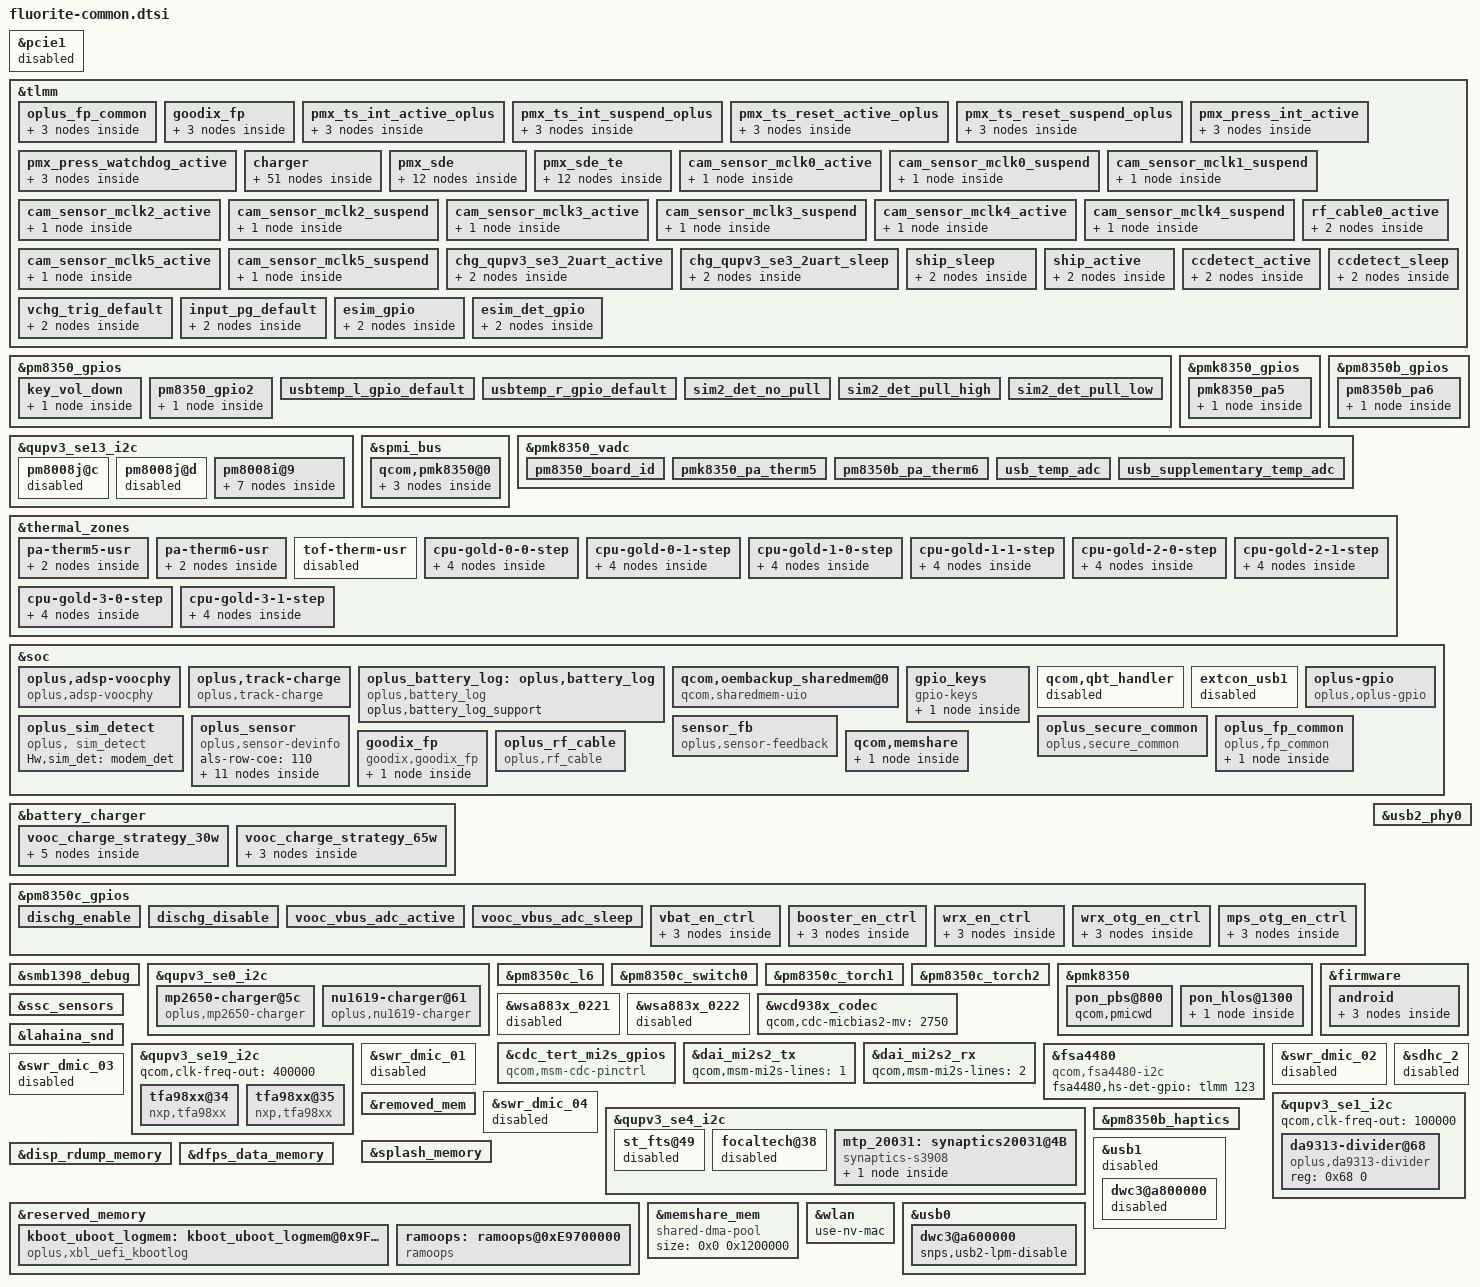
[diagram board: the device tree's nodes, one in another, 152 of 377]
//lahaina-pcie.dtsi
&pcie1 {
		status = "disabled";
};



//lahaina-pinctrl.dtsi

&tlmm {
	//#ifdef OPLUS_FEATURE_FINGERPRINT
	oplus_fp_common{
		gpio_id2_default: gpio_id2_default {
			mux {
				pins = "gpio119";
				function = "gpio";
			};
			config {
				pins = "gpio119";
				drive-strength = <2>;
				bias-pull-up;
				input-enable;
			};
		};
	};
	goodix_fp{
		gpio_goodix_irq_default: gpio_goodix_irq_default {
			mux {
				pins = "gpio38";
				function = "gpio";
			};
			config {
				pins = "gpio38";
				drive-strength = <2>;
				bias-disable;
				input-enable;
			};
		};
	};
	//#endif /*OPLUS_FEATURE_FINGERPRINT*/

	/* add pingrp for touchscreen */
	pmx_ts_int_active_oplus {
		ts_int_active: ts_int_active {
			mux {
				pins = "gpio23";
				function = "gpio";
			};

			config {
				pins = "gpio23";
				drive-strength = <8>;
				bias-disable;
				input-enable;
			};
		};
	};

	pmx_ts_int_suspend_oplus {
		ts_int_suspend1: ts_int_suspend1 {
			mux {
				pins = "gpio23";
				function = "gpio";
			};

			config {
				pins = "gpio23";
				drive-strength = <8>;
				//bias-pull-down;
				bias-pull-up;
				input-enable;
			};
		};
	};

	pmx_ts_reset_active_oplus {
		ts_reset_active: ts_reset_active {
			mux {
				pins = "gpio22";
				function = "gpio";
			};

			config {
				pins = "gpio22";
				drive-strength = <8>;
				output-low;
				bias-disable;
			};
		};
	};

	pmx_ts_reset_suspend_oplus {
		ts_reset_suspend1: ts_reset_suspend1 {
			mux {
				pins = "gpio22";
				function = "gpio";
			};

			config {
				pins = "gpio22";
				drive-strength = <2>;
				bias-pull-down;
			};
		};
	};


	pmx_press_int_active {
		press_int_active: press_int_active {
			mux {
				pins = "gpio51";
				function = "gpio";
			};

			config {
				pins = "gpio51";
				drive-strength = <2>;
				bias-disable;
				input-enable;
			};
		};
	};

	pmx_press_watchdog_active {
		watchdog_active: watchdog_active {
			mux {
				pins = "gpio97";
				function = "gpio";
			};

			config {
				pins = "gpio97";
				drive-strength = <2>;
				bias-disable;
				output-high;
			};
		};
	};


// #ifdef OPLUS_FEATURE_CHG_BASIC
	charger {
		idt_int_active: idt_int_active {
			mux {
				pins = "gpio7";
				function = "gpio";
			};

			config {
				pins = "gpio7";
				drive-strength = <2>;
				input-enable;
				/*bias-pull-up; PULL UP*/
				bias-disable;
			};
		};

		idt_int_sleep: idt_int_sleep {
			mux {
				pins = "gpio7";
				function = "gpio";
			};

			config {
				pins = "gpio7";
				drive-strength = <2>;
				bias-disable;
			};
		};

		idt_int_default: idt_int_default {
			mux {
				pins = "gpio7";
				function = "gpio";
			};

			config {
				pins = "gpio7";
				drive-strength = <2>;
				bias-disable;
			};
		};

		idt_connect_active: idt_connect_active {
			mux {
				pins = "gpio116";
				function = "gpio";
			};

			config {
				pins = "gpio116";
				drive-strength = <2>;
				bias-disable;
				input-enable;
				/*bias-pull-up; PULL UP*/
			};
		};

		idt_connect_sleep: idt_connect_sleep {
			mux {
				pins = "gpio116";
				function = "gpio";
			};

			config {
				pins = "gpio116";
				drive-strength = <2>;
				bias-disable;
			};
		};

		idt_connect_default: idt_connect_default {
			mux {
				pins = "gpio116";
				function = "gpio";
			};

			config {
				pins = "gpio116";
				drive-strength = <2>;
				bias-disable;
			};
		};
		vt_sleep_active: vt_sleep_active {
			mux {
				pins = "gpio46";
				function = "gpio";
			};

			config {
				pins = "gpio46";
				drive-strength = <2>;
				bias-pull-up;
			};
		};

		vt_sleep_sleep: vt_sleep_sleep {
			mux {
				pins = "gpio46";
				function = "gpio";
			};

			config {
				pins = "gpio46";
				drive-strength = <2>;
				bias-pull-down;
			};
		};

		vt_sleep_default: vt_sleep_default {
			mux {
				pins = "gpio46";
				function = "gpio";
			};

			config {
				pins = "gpio46";
				drive-strength = <2>;
				bias-pull-up;
			};
		};

		ext2_wireless_otg_en_active: ext2_wireless_otg_en_active {
			mux {
				pins = "gpio85";
				function = "gpio";
			};

			config {
				pins = "gpio85";
				drive-strength = <2>;
				bias-disable;
			};
		};

		ext2_wireless_otg_en_sleep: ext2_wireless_otg_en_sleep {
			mux {
				pins = "gpio85";
				function = "gpio";
			};

			config {
				pins = "gpio85";
				drive-strength = <2>;
				bias-disable;
			};
		};

		ext2_wireless_otg_en_default: ext2_wireless_otg_en_default {
			mux {
				pins = "gpio85";
				function = "gpio";
			};

			config {
				pins = "gpio85";
				drive-strength = <2>;
				bias-disable;
			};
		};

		ext1_wired_otg_en_active: ext1_wired_otg_en_active {
			mux {
				pins = "gpio26";
				function = "gpio";
			};

			config {
				pins = "gpio26";
				drive-strength = <2>;
				bias-disable;
			};
		};

		ext1_wired_otg_en_sleep: ext1_wired_otg_en_sleep {
			mux {
				pins = "gpio26";
				function = "gpio";
			};

			config {
				pins = "gpio26";
				drive-strength = <2>;
				bias-disable;
			};
		};

		ext1_wired_otg_en_default: ext1_wired_otg_en_default {
			mux {
				pins = "gpio26";
				function = "gpio";
			};

			config {
				pins = "gpio26";
				drive-strength = <2>;
				bias-disable;
			};
		};

		wls_pg_default: wls_pg_default {
			mux {
				pins = "gpio164";
				function = "gpio";
			};

			config {
				pins = "gpio164";
				drive-strength = <2>;
				bias-disable;
				output-high;
			};
		};

		wls_pg_active: wls_pg_active {
			mux {
				pins = "gpio164";
				function = "gpio";
			};

			config {
				pins = "gpio164";
				drive-strength = <2>;
				bias-disable;
				output-low;
			};
		};
	};
// #endif OPLUS_FEATURE_CHG_BASIC

	pmx_sde: pmx_sde {
		sde_dsi_active: sde_dsi_active {
			mux {
				pins = "gpio24";
				function = "gpio";
			};

			config {
				pins = "gpio24";
				drive-strength = <8>;   /* 8 mA */
				bias-disable = <0>;   /* no pull */
			};
		};

		sde_dsi_suspend: sde_dsi_suspend {
			mux {
				pins = "gpio24";
				function = "gpio";
			};

			config {
				pins = "gpio24";
				drive-strength = <2>;   /* 2 mA */
				bias-pull-down;         /* PULL DOWN */
			};
		};

		sde_dsi1_active: sde_dsi1_active {
			mux {
				pins = "gpio25";
				function = "gpio";
			};

			config {
				pins = "gpio25";
				drive-strength = <8>;   /* 8 mA */
				bias-disable = <0>;   /* no pull */
			};
		};

		sde_dsi1_suspend: sde_dsi1_suspend {
			mux {
				pins = "gpio25";
				function = "gpio";
			};

			config {
				pins = "gpio25";
				drive-strength = <2>;   /* 2 mA */
				bias-pull-down;         /* PULL DOWN */
			};
		};
	};

	pmx_sde_te: pmx_sde_te {
		sde_te_active: sde_te_active {
			mux {
				pins = "gpio82";
				function = "mdp_vsync";
			};

			config {
				pins = "gpio82";
				drive-strength = <2>;   /* 2 mA */
				bias-pull-down;         /* PULL DOWN */
			};
		};

		sde_te_suspend: sde_te_suspend {
			mux {
				pins = "gpio82";
				function = "mdp_vsync";
			};

			config {
				pins = "gpio82";
				drive-strength = <2>;   /* 2 mA */
				bias-pull-down;         /* PULL DOWN */
			};
		};

		sde_te1_active: sde_te1_active {
			mux {
				pins = "gpio83";
				function = "mdp_vsync";
			};

			config {
				pins = "gpio83";
				drive-strength = <2>;   /* 2 mA */
				bias-pull-down;         /* PULL DOWN */
			};
		};

		sde_te1_suspend: sde_te1_suspend {
			mux {
				pins = "gpio83";
				function = "mdp_vsync";
			};

			config {
				pins = "gpio83";
				drive-strength = <2>;   /* 2 mA */
				bias-pull-down;         /* PULL DOWN */
			};
		};
	};

	cam_sensor_mclk0_active {

		config {
			/* #ifdef OPLUS_FEATURE_CAMERA_COMMON */
			drive-strength = <6>; /* 6 MA */
			/* #else */
			// drive-strength = <2>; /* 2 MA */
			/* #endif */
		};
	};
	cam_sensor_mclk0_suspend {

		config {
			/* #ifdef OPLUS_FEATURE_CAMERA_COMMON */
			drive-strength = <6>; /* 6 MA */
			/* #else */
			// drive-strength = <2>; /* 2 MA */
			/* #endif */
		};
	};
	cam_sensor_mclk1_suspend {

		config {
			/* #ifdef OPLUS_FEATURE_CAMERA_COMMON */
			drive-strength = <6>; /* 6 MA */
			/* #else */
			// drive-strength = <2>; /* 2 MA */
			/* #endif */
		};
	};

	cam_sensor_mclk2_active {

		config {
			/* #ifdef OPLUS_FEATURE_CAMERA_COMMON */
			drive-strength = <6>; /* 6 MA */
			/* #else */
			// drive-strength = <2>; /* 2 MA */
			/* #endif */
		};
	};

	cam_sensor_mclk2_suspend {

		config {
			/* #ifdef OPLUS_FEATURE_CAMERA_COMMON */
			drive-strength = <6>; /* 6 MA */
			/* #else */
			// drive-strength = <2>; /* 2 MA */
			/* #endif */
		};
	};

	cam_sensor_mclk3_active {

		config {
			/* #ifdef OPLUS_FEATURE_CAMERA_COMMON */
			drive-strength = <6>; /* 6 MA */
			/* #else */
			// drive-strength = <2>; /* 2 MA */
			/* #endif */
		};
	};

	cam_sensor_mclk3_suspend {

		config {
			/* #ifdef OPLUS_FEATURE_CAMERA_COMMON */
			drive-strength = <6>; /* 6 MA */
			/* #else */
			// drive-strength = <2>; /* 2 MA */
			/* #endif */
		};
	};

	cam_sensor_mclk4_active {

		config {
			/* #ifdef OPLUS_FEATURE_CAMERA_COMMON */
			drive-strength = <6>; /* 6 MA */
			/* #else */
			// drive-strength = <2>; /* 2 MA */
			/* #endif */
		};
	};

	cam_sensor_mclk4_suspend {

		config {
			/* #ifdef OPLUS_FEATURE_CAMERA_COMMON */
			drive-strength = <6>; /* 6 MA */
			/* #else */
			// drive-strength = <2>; /* 2 MA */
			/* #endif */
		};
	};

	cam_sensor_mclk5_active {

		config {
			/* #ifdef OPLUS_FEATURE_CAMERA_COMMON */
			drive-strength = <6>; /* 6 MA */
			/* #else */
			// drive-strength = <2>; /* 2 MA */
			/* #endif */
		};
	};

	cam_sensor_mclk5_suspend {

		config {
			/* #ifdef OPLUS_FEATURE_CAMERA_COMMON */
			drive-strength = <6>; /* 6 MA */
			/* #else */
			// drive-strength = <2>; /* 2 MA */
			/* #endif */
		};
	};

	rf_cable0_active: rf_cable0_active {
		mux {
			pins = "gpio91";
			function = "gpio";
		};
		config {
			pins = "gpio91";
			drive-strength = <2>;
			input-enable;
			bias-pull-up;
		};
	};
};



//lahaina-pmic-overlay.dtsi
&pm8350_gpios {
	///delete-node/ key_vol_up;
	key_vol_down {
		key_vol_down_default: key_vol_down_default {
			pins = "gpio6";
			function = "normal";
			input-enable;
			bias-pull-up;
			power-source = <1>;
		};
	};
};

&qupv3_se13_i2c {
	pm8008j@c {
		status = "disabled";
	};

	pm8008j@d {
		status = "disabled";
	};

	pm8008i@9 {

		qcom,pm8008i-regulator {
			vdd_l3_l4-supply = <&S1C>;
			vdd_l5-supply = <&BOB>;


			//L2I: pm8008i_l2: regulator@4100 {
			regulator@4100 {
				reg = <0x4100>;
				regulator-name = "pm8008i_l2";
				regulator-min-microvolt = <944000>;
				regulator-max-microvolt = <1256000>;
				qcom,min-dropout-voltage = <150000>;
				qcom,hpm-min-load = <30000>;
			};

			//L3I: pm8008i_l3: regulator@4200 {
			regulator@4200 {
				reg = <0x4200>;
				regulator-name = "pm8008i_l3";
				regulator-min-microvolt = <1696000>;
				regulator-max-microvolt = <1800000>;
				qcom,min-dropout-voltage = <70000>;
			};

			//L4I: pm8008i_l4: regulator@4300 {
			regulator@4300 {
				reg = <0x4300>;
				regulator-name = "pm8008i_l4";
				regulator-min-microvolt = <1696000>;
				regulator-max-microvolt = <1800000>;
				qcom,min-dropout-voltage = <70000>;
			};

			//L5I: pm8008i_l5: regulator@4400 {
			regulator@4400 {
				reg = <0x4400>;
				regulator-name = "pm8008i_l5";
				regulator-min-microvolt = <2696000>;
				regulator-max-microvolt = <3000000>;
				qcom,min-dropout-voltage = <200000>;
			};

			//L6I: pm8008i_l6: regulator@4500 {
			regulator@4500 {
				reg = <0x4500>;
				regulator-name = "pm8008i_l6";
				regulator-min-microvolt = <2696000>;
				regulator-max-microvolt = <3000000>;
/*endif*/
				qcom,min-dropout-voltage = <200000>;
			};

			//L7I: pm8008i_l7: regulator@4600 {
			regulator@4600 {
				reg = <0x4600>;
				regulator-name = "pm8008i_l7";
				regulator-min-microvolt = <2696000>;
				regulator-max-microvolt = <3000000>;
				qcom,min-dropout-voltage = <200000>;
			};
		};
	};

};



&pm8350_gpios {

	pm8350_gpio2 {
		pm8350_gpio2_default: pm8350_gpio2_default {
			pins = "gpio2";
			bias-high-impedance;
		};
	};
};

&pmk8350_gpios {
	pmk8350_pa5 {
		pmk8350_pa5_therm_default: pmk8350_pa5_therm_default {
			pins = "gpio3";
			bias-high-impedance;
		};
	};

};

&pm8350b_gpios {
	pm8350b_pa6 {
		pm8350b_pa6_therm_default: pm8350b_pa6_therm_default {
			pins = "gpio1";
			bias-high-impedance;
		};
	};

};

&spmi_bus {
	qcom,pmk8350@0 {
		pm8350_adc_tm_iio: adc_tm_iio@3400 {
			/* Alternate ADC_TM DT node */
			compatible = "qcom,adc-tm7-iio";
			/* With this entry, a feature-reduced
			version of the driver is initialized (only
			thermistor reads, no interrupt functionality
			for exposed thermistors) */
			reg = <0x3400>;
			#thermal-sensor-cells = <1>;
			#address-cells = <1>;
			#size-cells = <0>;
			io-channels = <&pmk8350_vadc PM8350B_ADC7_GPIO1_100K_PU>,
				      <&pmk8350_vadc PMK8350_ADC7_AMUX_THM4_100K_PU>;
			/* Similar to io-channels in actual ADC_TM node,
			for reading thermistor temperature from
			VADC */

			pm8350b_pa_therm6 {
				/* ADC_TM child node, similar to previous */
				reg = <PM8350B_ADC7_GPIO1_100K_PU>;
				qcom,ratiometric;
				qcom,hw-settle-time = <200>;
			};
			pmk8350_pa_therm5 {
				/* ADC_TM child node, similar to previous */
				reg = <PMK8350_ADC7_AMUX_THM4_100K_PU>;
				qcom,ratiometric;
				qcom,hw-settle-time = <200>;
			};

		};
	};
};

&pmk8350_vadc {
	pinctrl-names = "default";
	//pinctrl-0 = <&pm8350_rear_tof_therm_default>;
	pinctrl-0 = <&pm8350_gpio2_default &pmk8350_pa5_therm_default &pm8350b_pa6_therm_default>;

	pm8350_board_id {
		reg = <PM8350_ADC7_GPIO1>;
		label = "pm8350_board_id";
		//qcom,ratiometric;
		qcom,hw-settle-time = <200>;
		qcom,pre-scaling = <1 1>;
	};

	pmk8350_pa_therm5 {
		reg = <PMK8350_ADC7_AMUX_THM4_100K_PU>;
		label = "pmk8350_pa_therm5";
		qcom,ratiometric;
		qcom,hw-settle-time = <200>;
		qcom,pre-scaling = <1 1>;
	};

	pm8350b_pa_therm6 {
		reg = <PM8350B_ADC7_GPIO1_100K_PU>;
		label = "pm8350b_pa_therm6";
		qcom,ratiometric;
		qcom,hw-settle-time = <200>;
		qcom,pre-scaling = <1 1>;
	};
};

&thermal_zones {
	pa-therm5-usr {
		polling-delay-passive = <0>;
		polling-delay = <0>;
		thermal-governor = "user_space";
		thermal-sensors = <&pm8350_adc_tm_iio PMK8350_ADC7_AMUX_THM4_100K_PU>;
		/* phandle and channel number of added channel */
		wake-capable-sensor;
		trips {
			active-config0 {
				temperature = <55000>;
				hysteresis = <1000>;
				type = "passive";
			};
		};
	};

	pa-therm6-usr {
		polling-delay-passive = <0>;
		polling-delay = <0>;
		thermal-governor = "user_space";
		thermal-sensors = <&pm8350_adc_tm_iio PM8350B_ADC7_GPIO1_100K_PU>;
		/* phandle and channel number of added channel */
		wake-capable-sensor;
		trips {
			active-config0 {
				temperature = <55000>;
				hysteresis = <1000>;
				type = "passive";
			};
		};
	};
};

&soc {
	oplus,adsp-voocphy {
		compatible = "oplus,adsp-voocphy";
	};
};

&battery_charger {
	//for oplus chg framework:
        oplus,chg_ops = "ext-mp2650";
	qcom,smart_charging_screenoff;
	qcom,voocphy_support = <1>;
	qcom,input_current_charger_ma = <2000>;
	qcom,pd_input_current_charger_ma = <2000>;
	qcom,qc_input_current_charger_ma = <2000>;

	qcom,input_current_usb_ma = <500>;

	qcom,input_current_cdp_ma = <1500>;
	qcom,input_current_led_ma = <1200>;
	qcom,input_current_led_ma_high = <1800>;
	qcom,input_current_led_ma_warm = <1800>;
	qcom,input_current_led_ma_normal = <2000>;
	qcom,led_warm_bat_decidegc = <350>;
	qcom,led_high_bat_decidegc = <370>;

	qcom,input_current_camera_ma = <1200>;

	qcom,input_current_vooc_led_ma_high = <1800>;
	qcom,input_current_vooc_led_ma_warm = <1800>;
	qcom,input_current_vooc_led_ma_normal = <3600>;
	qcom,input_current_vooc_ma_normal = <3600>;
	qcom,vooc_temp_bat_normal_decidegc = <350>;
	qcom,input_current_vooc_ma_warm = <3200>;
	qcom,vooc_temp_bat_warm_decidegc = <370>;
	qcom,input_current_vooc_ma_high = <2200>;
	qcom,vooc_temp_bat_hot_decidegc = <440>;

	qcom,charger_current_vooc_ma_normal = <1800>;

	qcom,chg_ctrl_by_calling;
	qcom,input_current_calling_ma = <1500>;

	//qcom,input_current_led_ma_overtemp = <900>;
	qcom,overtemp_bat_decidegc = <350>;
	qcom,iterm_disabled = <0>;
	qcom,iterm_ma = <130>;
	qcom,recharge-mv = <100>;
	qcom,batt_capacity_mah = <4500>;/*typical capacity*/
	//qcom,batt_capacity_mah = <4400>; /*rated capacity*/

	qcom,removed_bat_decidegc = <190>;  /*<-19C*/

	qcom,cold_bat_decidegc = <20>;  /*-2C~0C*/
	qcom,temp_cold_vfloat_mv = <3980>;
	qcom,temp_cold_fastchg_current_ma = <300>;

	qcom,little_cold_bat_decidegc = <0>;	/*0C~5C*/
	qcom,temp_little_cold_vfloat_mv = <4435>;
	qcom,temp_little_cold_fastchg_current_ma_high = <1100>;
	qcom,temp_little_cold_fastchg_current_ma_low = <1100>;
	qcom,temp_little_cold_fastchg_current_ma = <1100>;
	qcom,pd_temp_little_cold_fastchg_current_ma_high = <2000>;
	qcom,pd_temp_little_cold_fastchg_current_ma_low = <1450>;
	qcom,qc_temp_little_cold_fastchg_current_ma_high = <2000>;
	qcom,qc_temp_little_cold_fastchg_current_ma_low = <1450>;

	qcom,cool_bat_decidegc = <50>;	/*5C~12C*/
	qcom,temp_cool_vfloat_mv = <4435>;
	qcom,temp_cool_fastchg_current_ma_high = <1100>;
	qcom,temp_cool_fastchg_current_ma_low = <1100>;
	qcom,pd_temp_cool_fastchg_current_ma_high = <2000>;
	qcom,pd_temp_cool_fastchg_current_ma_low = <2000>;
	qcom,qc_temp_cool_fastchg_current_ma_high = <2000>;
	qcom,qc_temp_cool_fastchg_current_ma_low = <2000>;

	qcom,little_cool_bat_decidegc = <120>;	/*12C~16C*/
	qcom,temp_little_cool_vfloat_mv = <4435>;
	qcom,temp_little_cool_fastchg_current_ma = <1100>;
	qcom,pd_temp_little_cool_fastchg_current_ma = <2000>;
	qcom,qc_temp_little_cool_fastchg_current_ma = <2000>;

	qcom,normal_bat_decidegc = <160>;	/*16C~44C*/
	qcom,temp_normal_fastchg_current_ma = <1100>;
	qcom,temp_normal_vfloat_mv = <4435>;
	qcom,pd_temp_normal_fastchg_current_ma = <2000>;
	qcom,qc_temp_normal_fastchg_current_ma = <2000>;

	qcom,warm_bat_decidegc = <450>;		/*45C~53C*/ /*8pin Bat Vooc project need add 3 degree C*/
	qcom,temp_warm_vfloat_mv = <4130>;
	qcom,temp_warm_fastchg_current_ma = <600>;
	qcom,pd_temp_warm_fastchg_current_ma = <600>;
	qcom,qc_temp_warm_fastchg_current_ma = <600>;
	qcom,temp_warm_fastchg_current_ma_led_on = <250>;

	qcom,hot_bat_decidegc = <530>;

	qcom,non_standard_vfloat_mv = <3980>;
	qcom,non_standard_fastchg_current_ma = <512>;

	qcom,short_c_bat_cv_mv = <4330>;
	qcom,short_c_bat_vfloat_mv = <3800>;
	qcom,short_c_bat_fastchg_current_ma = <512>;

	qcom,cold_vfloat_sw_limit = <3930>;
	qcom,little_cold_vfloat_sw_limit = <4385>;
	qcom,cool_vfloat_sw_limit = <4385>;
	qcom,little_cool_vfloat_sw_limit = <4385>;
	qcom,normal_vfloat_sw_limit = <4385>;
	qcom,warm_vfloat_sw_limit = <4080>;
	qcom,non_standard_vfloat_sw_limit = <3930>;
	qcom,short_c_bat_vfloat_sw_limit = <3750>;

	qcom,max_chg_time_sec = <36000>;
	qcom,charger_hv_thr = <9900>;
	qcom,charger_recv_thr = <9500>;
	qcom,charger_lv_thr = <3400>;
	qcom,vbatt_full_thr = <4435>;
	qcom,vbatt_hv_thr = <4600>;
	qcom,vfloat_step_mv = <8>;
	qcom,non_standard_vfloat_over_sw_limit = <3990>;
	qcom,cold_vfloat_over_sw_limit = <3990>;
	qcom,little_cold_vfloat_over_sw_limit = <4445>;
	qcom,cool_vfloat_over_sw_limit = <4445>;
	qcom,little_cool_vfloat_over_sw_limit = <4445>;
	qcom,normal_vfloat_over_sw_limit = <4445>;
	qcom,warm_vfloat_over_sw_limit = <4140>;

	qcom,vbatt_power_off = <3300>;
	qcom,vbatt_soc_1 = <3310>;
	qcom,vooc_project = <3>;
	qcom,vbatt_num = <2>;
	qcom,ffc_support;
	qcom,dual_ffc;
	recharge_after_full;
	qcom,wireless_support;
	qcom,wpc_no_chargerpump;
	qcom,fg_info_package_read_support;

	qcom,normal_vterm_hw_inc = <18>;
	qcom,non_normal_vterm_hw_inc = <18>;

	qcom,ff1_normal_fastchg_ma = <550>;
	qcom,ff1_warm_fastchg_ma = <550>;
	qcom,ffc2_normal_fastchg_ma = <350>;/*12C~35c*/
	qcom,ffc2_temp_warm_decidegc = <350>;
	qcom,ffc2_warm_fastchg_ma = <400>;/*35C~40c*/
	qcom,ffc2_temp_high_decidegc = <400>;
	qcom,ffc2_temp_low_decidegc = <120>;
	qcom,ffc2_exit_step_ma = <100>;
	qcom,ff1_exit_step_ma = <150>;
	qcom,ff1_warm_exit_step_ma = <150>;

	qcom,ffc_normal_vfloat_sw_limit = <4445>;
	qcom,ffc2_normal_vfloat_sw_limit = <4440>;
	qcom,ffc2_warm_vfloat_sw_limit = <4440>;
	qcom,ffc_temp_normal_vfloat_mv = <4500>;
	qcom,ffc1_temp_normal_vfloat_mv = <4500>;
	qcom,ffc2_temp_normal_vfloat_mv = <4500>;
	qcom,ffc_normal_vfloat_over_sw_limit = <4500>;
	qcom,ffc1_normal_vfloat_over_sw_limit = <4500>;
	qcom,ffc2_normal_vfloat_over_sw_limit = <4500>;

	qcom,default_iterm_ma = <130>;
	qcom,default_temp_normal_fastchg_current_ma = <1100>;
	qcom,default_normal_vfloat_sw_limit = <4385>;
	qcom,default_temp_normal_vfloat_mv = <4435>;
	qcom,default_normal_vfloat_over_sw_limit = <4445>;

	qcom,default_temp_little_cool_fastchg_current_ma = <1100>;
	qcom,default_little_cool_vfloat_sw_limit = <4385>;
	qcom,default_temp_little_cool_vfloat_mv = <4435>;
	qcom,default_little_cool_vfloat_over_sw_limit = <4445>;

	oplus,aging_ffc_version = <1>;

	///qcom,offset_temp = <30>;
	//for control:
	//qcom,suspend_after_full;
	qcom,check_batt_full_by_sw;
	qcom,external_gauge;
	qcom,chg_ctrl_by_lcd;
	qcom,chg_ctrl_by_vooc;
	qcom,chg_ctrl_by_camera;
	qcom,sw_vfloat_over_protect_enable;

	//for PD9V or QC9V
	qcom,vbatt_pdqc_to_5v_thr = <4100>;

	qcom,vooc_show_ui_soc_decimal;
	qcom,ui_soc_decimal_speedmin = <20>;//2A

	qcom,vooc_vbus_adc-gpio = <&pm8350c_gpios 8 0x00>;
	qcom,ship-gpio = <&tlmm 29 0x00>;
	qcom,ccdetect-gpio = <&tlmm 44 0x00>;
	qcom,vchg_trig-gpio = <&tlmm 80 0x00>;
	qcom,dischg-gpio = <&pm8350c_gpios 9 0x00>;
	pinctrl-names = "vooc_vbus_adc_active", "vooc_vbus_adc_sleep",
					"ship_active", "ship_sleep",
					"vchg_trig_default",
					"usbtemp_l_gpio_default", "usbtemp_r_gpio_default",
					"dischg_enable", "dischg_disable",
					"input_pg_default",
					"ccdetect_active", "ccdetect_sleep",
					"chg_qupv3_se3_2uart_active", "chg_qupv3_se3_2uart_sleep";

	pinctrl-0 = <&vooc_vbus_adc_active>;
	pinctrl-1 = <&vooc_vbus_adc_sleep>;
	pinctrl-2 = <&ship_active>;
	pinctrl-3 = <&ship_sleep>;
	pinctrl-4 = <&vchg_trig_default>;
	pinctrl-5 = <&usbtemp_l_gpio_default>;
	pinctrl-6 = <&usbtemp_r_gpio_default>;
	pinctrl-7 = <&dischg_enable>;
	pinctrl-8 = <&dischg_disable>;
	pinctrl-9 = <&input_pg_default>;
	pinctrl-10 = <&ccdetect_active>;
	pinctrl-11 = <&ccdetect_sleep>;
	pinctrl-12 = <&chg_qupv3_se3_2uart_active>;
	pinctrl-13 = <&chg_qupv3_se3_2uart_sleep>;
	
	qcom,vooc-max-input-volt-support = <10000>;     //10V
	qcom,vooc-max-input-current-support = <6500>;   //6A
	vooc_charge_strategy_30w {
		strategy_1 {
			capacity_range = <0 75>;
			temp_range = <120 160>;
			input_current = <4000 4450 0
					3000 4470 0
					2000 4480 0>;
			};
		strategy_2 {
			capacity_range = <0 75>;
			temp_range = <160 410>;
			input_current = <6000 4200 900
					5000 4200 0
					4500 4450 0
					4000 4450 0
					3000 4470 0
					2000 4480 0>;
		};
		strategy_3 {
			capacity_range = <0 75>;
			temp_range = <410 420>;
			input_current = <4000 4470 0
					2000 4480 0>;
		};
		strategy_4 {
			capacity_range = <0 75>;
			temp_range = <420 425>;
			input_current = <4000 4480 0>;
		};
		strategy_5 {
			capacity_range = <0 75>;
			temp_range = <425 435>;
			input_current = <3000 4480 0>;
		};
	};

	vooc_charge_strategy_65w {
		strategy_1 {
			capacity_range = <0 50>;
			temp_range = <120 160>;
			input_current = <6000 4200 0
					4000 4454 0
					2000 4494 0
					1500 4500 0>;
		};
		strategy_2 {
			capacity_range = <0 50>;
			temp_range = <160 370>;
			input_current = <6500 4200 0
					6000 4250 300
					5500 4300 400
					4500 4454 780
					3500 4454 0
					2000 4494 0
					1500 4500 0>;
		};
		strategy_3 {
			capacity_range = <0 90>;
			temp_range = <370 430>;
			input_current = <6500 4200 0
					6000 4250 300
					5500 4300 400
					4500 4454 780
					3500 4454 0
					2000 4494 0
					1600 4500 0>;
		};
	};
};

&pm8350_gpios {
	/delete-node/ pm8350_rear_tof_therm_default;
	usbtemp_l_gpio_default: usbtemp_l_gpio_default {
		pins = "gpio1"; /* GPIO 1 */
		function = "normal"; /* normal */
		bias-high-impedance; /* DISABLE GPIO1 for ADC*/
    };
	usbtemp_r_gpio_default: usbtemp_r_gpio_default {
        pins = "gpio3"; /* GPIO 3 */
		function = "normal"; /* normal */
        bias-high-impedance; /* DISABLE GPIO3 for ADC*/
    };
};

&pmk8350_vadc {
	/delete-node/ pm8350_rear_tof_therm;
	usb_temp_adc {
		reg = <PM8350_ADC7_AMUX_THM5_100K_PU>;
		label = "usb_temp_adc";
		qcom,pre-scaling = <1 1>;
		qcom,ratiometric;
		qcom,hw-settle-time = <200>;
	};
	usb_supplementary_temp_adc {
		reg = <PM8350_ADC7_GPIO2_100K_PU>;
		label = "usb_supplementary_temp_adc";
		qcom,pre-scaling = <1 1>;
		qcom,ratiometric;
		qcom,hw-settle-time = <200>;
	};
};

&battery_charger {
	io-channels	= <&pmk8350_vadc PM8350_ADC7_AMUX_THM5_100K_PU>,
					<&pmk8350_vadc PM8350_ADC7_GPIO2_100K_PU>;
	io-channel-names = "usb_temp_adc",
						"usb_supplementary_temp_adc";
};

&pm8350c_gpios {
	dischg_enable: dischg_enable {
		pins = "gpio9"; /* GPIO 9 */
		function = "normal"; /* normal */
		bias-disable; //No Pull
		power-source = <0>;//VIN0 3.3
		output-high; //digital output, no invert
		qcom,drive-strength = <3>; //LOW strength
		//drive-push-pull;//CMOS
	};

	dischg_disable: dischg_disable {
		pins = "gpio9"; /* GPIO 9 */
		function = "normal"; /* normal */
		bias-disable; //No Pull
		power-source = <0>;//VIN0 3.3
		output-low; //digital output, no invert
		qcom,drive-strength = <3>; //LOW strength
		//drive-push-pull;//CMOS
	};
};

&pm8350c_gpios {
	vooc_vbus_adc_active: vooc_vbus_adc_active {
		pins = "gpio8";
		function = "normal";
		qcom,drive-strength = <2>;
		power-source = <1>;
		bias-pull-up;
		output-high;
	};

	vooc_vbus_adc_sleep: vooc_vbus_adc_sleep {
		pins = "gpio8";
		function = "normal";
		qcom,drive-strength = <2>;
		power-source = <1>;
		bias-pull-down;
		output-low;
	};
};

&tlmm {
	chg_qupv3_se3_2uart_active: chg_qupv3_se3_2uart_active {
		mux {
			pins = "gpio18", "gpio19";
			function = "qup3";
		};

		config {
			pins = "gpio18", "gpio19";
			drive-strength = <2>;
			bias-disable;
		};
	};

	chg_qupv3_se3_2uart_sleep: chg_qupv3_se3_2uart_sleep {
		mux {
			pins = "gpio18", "gpio19";
			function = "gpio";
		};

		config {
			pins = "gpio18", "gpio19";
			drive-strength = <2>;
			input-enable;
			bias-pull-down;
		};
	};

	ship_sleep: ship_sleep {
		mux {
			pins = "gpio29";
			function = "gpio";
		};

		config {
			pins = "gpio29";
			drive-strength = <2>;
			bias-pull-down;
			output-low;
		};
	};

	ship_active: ship_active {
		mux {
			pins = "gpio29";
			function = "gpio";
		};

		config {
			pins = "gpio29";
			drive-strength = <2>;
			bias-pull-up;
			output-high;
		};
	};

	ccdetect_active: ccdetect_active {
		mux {
			pins = "gpio44";
			function = "gpio";
		};

		config {
			pins = "gpio44";
			drive-strength = <2>;
			input-enable;
			//bias-pull-up; /*PULL UP*/
			bias-disable;
		};
	};

	ccdetect_sleep: ccdetect_sleep {
		mux {
			pins = "gpio44";
			function = "gpio";
		};

		config {
			pins = "gpio44";
			drive-strength = <2>;
			//output-low;
			//bias-pull-down; /*PULL DOWN*/
			input-enable;
			bias-disable;
		};
	};

	vchg_trig_default: vchg_trig_default {
		mux {
			pins = "gpio80";
			function = "gpio";
		};

		config {
			pins = "gpio80";
			drive-strength = <2>;
			input-enable;
			bias-disable;
		};
	};

	input_pg_default: input_pg_default {
		mux {
			pins = "gpio39";
			function = "gpio";
		};

		config {
			pins = "gpio39";
			drive-strength = <2>;
			input-enable;
			//bias-pull-up; /*PULL UP*/
			bias-pull-down;
		};
	};
};

&smb1398_debug {
	status = "ok";
};

&usb2_phy0 {
	qcom,param-override-seq =
		<0xe7 0x6c
		0x0e 0x70
		0x17 0x74
		0x03 0x78>;
};

&soc {
	oplus,track-charge {
		compatible = "oplus,track-charge";
		track,fast_chg_break_t_thd = <1000>;
		track,general_chg_break_t_thd = <200>;
		track,voocphy_type = <1>;
		track,wls_max_power = <30000>;
		track,wired_max_power = <65000>;
		track,wls_bpp_chg_scheme = <0>;
		track,wls_epp_chg_scheme = <0>;
		track,wls_fast_chg_scheme = <0>;
		track,wired_fast_chg_scheme = <1>;
	};

	oplus_battery_log: oplus,battery_log {
		compatible = "oplus,battery_log";
		oplus,battery_log_support;
	};
};
//#endif /*OPLUS_FEATURE_CHG_BASIC*/



//#lahaina-qupv3.dtsi
//#ifdef OPLUS_FEATRUE_ESIM
/*
&qupv3_se0_spi {
	status = "disabled";
};
*/
//#endif /* OPLUS_FEATRUE_ESIM */

&qupv3_se0_i2c {
// #ifdef OPLUS_FEATURE_CHG_BASIC
		status = "ok";
//else
//		status = "disabled";
// #endif OPLUS_FEATURE_CHG_BASIC
};

//#ifdef OPLUS_FEATRUE_ESIM
/*
&qupv3_se10_spi {
		status = "disabled";
};
*/
//#endif /* OPLUS_FEATRUE_ESIM */


//lahaina-regulators.dtsi
&pm8350c_l6 {
	/delete-property/ qcom,proxy-consumer-enable;
	/delete-property/ qcom,proxy-consumer-current;
};


//pm8350c.dtsi
&pm8350c_switch0 {
	qcom,led-mask = <1>; /* Channels 1 & 4 */
	qcom,symmetry-en;
};

&pm8350c_torch1 {
/*#ifdef OPLUS_FEATURE_CAMERA_COMMON*/
				qcom,max-current-ma = <25>;
				qcom,ires-ua = <5000>;
/*#endif*/
};
&pm8350c_torch2 {
/*#ifdef OPLUS_FEATURE_CAMERA_COMMON*/
				qcom,max-current-ma = <25>;
				qcom,ires-ua = <5000>;
/*#endif*/
};


//pmk8350.dtsi
&pmk8350 {
	pon_pbs@800 {
		//#ifdef OPLUS_FEATURE_QCOM_PMICWD
		qcom,pmicwd;
		//#endif /* OPLUS_FEATURE_QCOM_PMICWD */
	};
  
	pon_hlos@1300 {
			/*qcom,pon_2 {
				qcom,pon-type = <PON_POWER_ON_TYPE_RESIN>;
				linux,code = <KEY_VOLUMEDOWN>;
			};*/
			reg = <0x1300>, <0x800>;
			reg-names = "pon_hlos", "pon_pbs";
			qcom,kpdpwr-sw-debounce;
			qcom,pon_2 {
				qcom,pon-type = <PON_POWER_ON_TYPE_RESIN>;
				linux,code = <KEY_VOLUMEUP>;
			};
	};
};

//lahaina.dtsi
&firmware {
		android {
			vbmeta {
				parts = "vbmeta,boot,system,vendor,dtbo,vendor_boot";
				//parts = "vbmeta,boot,system,vendor,dtbo,recovery";
			};

			fstab {
				vendor {
					fsmgr_flags = "wait,slotselect,avb";
					//fsmgr_flags = "wait,avb";
				};
			};
		};
};


&soc {
	//#ifdef FEATURE_OPLUS_NV_BACKUP
	//add for creating a shared memory with uio for nv backup and restore
	qcom,oembackup_sharedmem@0 {
		compatible = "qcom,sharedmem-uio";
		reg = <0x0 0x280000>;
		reg-names = "oembackup";
		qcom,client-id = <0x00000004>;
	};
	//#endif /* FEATURE_OPLUS_NV_BACKUP */
};
&ssc_sensors {
		vdd-supply = <&pm8350c_l7>;
		vddio-supply = <&pm8350c_l8>;
};



//lahaina-audio-overlay.dtsi
&wsa883x_0221 {
	status = "disabled";
};

&wsa883x_0222 {
	status = "disabled";
};

&wcd938x_codec {
		//qcom,cdc-micbias2-mv = <1800>;
		qcom,cdc-micbias2-mv = <2750>;
};

&lahaina_snd {
	qcom,audio-routing =
		"AMIC1", "Analog Mic1",
		"Analog Mic1", "MIC BIAS1",
		"AMIC2", "Analog Mic2",
		"Analog Mic2", "MIC BIAS2",
		"AMIC3", "Analog Mic3",
		"Analog Mic3", "MIC BIAS3",
		"AMIC4", "Analog Mic4",
		"Analog Mic4", "MIC BIAS3",
		"AMIC5", "Analog Mic5",
		"Analog Mic5", "MIC BIAS4",
		"TX DMIC0", "Digital Mic0",
		"TX DMIC0", "MIC BIAS3",
		"TX DMIC1", "Digital Mic1",
		//"TX DMIC1", "MIC BIAS3",
		"TX DMIC1", "MIC BIAS1",
		"TX DMIC2", "Digital Mic2",
		"TX DMIC2", "MIC BIAS1",
		"TX DMIC3", "Digital Mic3",
		//"TX DMIC3", "MIC BIAS1",
		"TX DMIC3", "MIC BIAS3",
		"TX DMIC4", "Digital Mic4",
		"TX DMIC4", "MIC BIAS4",
		"TX DMIC5", "Digital Mic5",
		"TX DMIC5", "MIC BIAS4",
		"IN1_HPHL", "HPHL_OUT",
		"IN2_HPHR", "HPHR_OUT",
		"IN3_AUX", "AUX_OUT",
		"HAP_IN", "PCM_OUT",
		/*"WSA SRC0_INP", "SRC0",
		"TX SWR_INPUT", "SWR_MIC0 SWR_DMIC_OUTPUT",
		"TX SWR_INPUT", "SWR_MIC1 SWR_DMIC_OUTPUT",
		"TX SWR_INPUT", "SWR_MIC2 SWR_DMIC_OUTPUT",
		"TX SWR_INPUT", "SWR_MIC3 SWR_DMIC_OUTPUT",
		"VA SWR_INPUT", "SWR_MIC0 SWR_DMIC_OUTPUT",
		"VA SWR_INPUT", "SWR_MIC1 SWR_DMIC_OUTPUT",
		"VA SWR_INPUT", "SWR_MIC2 SWR_DMIC_OUTPUT",
		"VA SWR_INPUT", "SWR_MIC3 SWR_DMIC_OUTPUT",
		"WSA_TX DEC0_INP", "TX DEC0 MUX",
		"WSA_TX DEC1_INP", "TX DEC1 MUX",*/
		"RX_TX DEC0_INP", "TX DEC0 MUX",
		"RX_TX DEC1_INP", "TX DEC1 MUX",
		"RX_TX DEC2_INP", "TX DEC2 MUX",
		"RX_TX DEC3_INP", "TX DEC3 MUX",
		/*"SpkrLeft IN", "WSA_SPK1 OUT",
		"SpkrRight IN", "WSA_SPK2 OUT",*/
		"TX SWR_INPUT", "WCD_TX_OUTPUT",
		"VA SWR_INPUT", "VA_SWR_CLK",
		"VA SWR_INPUT", "WCD_TX_OUTPUT",
		"VA_AIF1 CAP", "VA_SWR_CLK",
		"VA_AIF2 CAP", "VA_SWR_CLK",
		"VA_AIF3 CAP", "VA_SWR_CLK",
		"VA DMIC0", "Digital Mic0",
		"VA DMIC1", "Digital Mic1",
		"VA DMIC2", "Digital Mic2",
		"VA DMIC3", "Digital Mic3",
		"VA DMIC4", "Digital Mic4",
		"VA DMIC5", "Digital Mic5",
		"VA DMIC0", "VA MIC BIAS3",
		//"VA DMIC1", "VA MIC BIAS3",
		"VA DMIC1", "VA MIC BIAS1",
		"VA DMIC2", "VA MIC BIAS1",
		//"VA DMIC3", "VA MIC BIAS1",
		"VA DMIC3", "VA MIC BIAS3",
		"VA DMIC4", "VA MIC BIAS4",
		"VA DMIC5", "VA MIC BIAS4";
	/*qcom,wsa-max-devs = <2>;*/
	qcom,wsa-max-devs = <0>;

	qcom,tert-mi2s-gpios = <&cdc_tert_mi2s_gpios>;
	oplus,speaker-pa = "nxp";
	qcom,msm-mbhc-hs-mic-max-threshold-mv = <2600>;
	qcom,msm-mbhc-hs-mic-min-threshold-mv = <75>;
	qcom,msm-mbhc-usbc-audio-supported = <1>;
	oplus,mbhc-check-irq-en = <1>;
	oplus,mbhc-headset-micbias-alwayon = <1>;

	/* #ifdef OPLUS_FEATURE_4CH_AEC */
	qcom,afe-rxtx-lb = <1>;
	/* #endif OPLUS_FEATURE_4CH_AEC */
};


&cdc_tert_mi2s_gpios {
	compatible = "qcom,msm-cdc-pinctrl";
	pinctrl-names = "aud_active", "aud_sleep";
	pinctrl-0 = <&tert_mi2s_sck_active &tert_mi2s_ws_active &tert_mi2s_sd0_active &tert_mi2s_sd1_active>;
	pinctrl-1 = <&tert_mi2s_sck_sleep &tert_mi2s_ws_sleep &tert_mi2s_sd0_sleep &tert_mi2s_sd1_sleep>;
};

&dai_mi2s2_tx {
	qcom,msm-mi2s-lines = <1>;
};

&dai_mi2s2_rx {
	qcom,msm-mi2s-lines = <2>;
};

/*Add for audio smartPA*/
&qupv3_se19_i2c {
        status = "ok";
        qcom,clk-freq-out = <400000>;
        tfa98xx@34 {
                compatible = "nxp,tfa98xx";
                reg = <0x34>;
                tfa9874_vdd-supply = <&S10B>;
                reset-gpio = <&tlmm 15 0x00>;
                tfa_min_range = <5000>;
                tfa_max_range = <8000>;
                tfa_channel = <1>;
                status = "ok";
        };
        tfa98xx@35 {
                compatible = "nxp,tfa98xx";
                reg = <0x35>;
                tfa9874_vdd-supply = <&S10B>;
                reset-gpio = <&tlmm 42 0x00>;
                tfa_min_range = <5000>;
                tfa_max_range = <8000>;
                tfa_channel = <0>;
                status = "ok";
        };
};

&fsa4480 {
	compatible = "qcom,fsa4480-i2c";
	status = "ok";
	fsa4480,hs-det-gpio = <&tlmm 123 0x00>;
};

/* #ifdef OPLUS_ARCH_EXTENDS */
&swr_dmic_01 {
	status = "disabled";
};

&swr_dmic_02 {
	status = "disabled";
};
&swr_dmic_03 {
	status = "disabled";
};
&swr_dmic_04 {
	status = "disabled";
};
/* #endif OPLUS_ARCH_EXTENDS */


//lahaina-mtp.dtsi

&tlmm {
	//#ifdef OPLUS_FEATRUE_ESIM
	esim_gpio: esim_gpio {
		mux {
			pins = "gpio6";
			function = "gpio";
		};
		config {
			pins = "gpio6";
			bias-disable; /* NO pull */
			drive-strength = <2>; /* 2 MA */
			output-high;
		};
	};

	esim_det_gpio: esim_det_gpio {
		mux {
			pins = "gpio47";
			function = "gpio";
		};
		config {
			pins = "gpio47";
			bias-disable; /* NO pull */
			drive-strength = <2>; /* 2 MA */
			output-high;
		};
	};
	//#endif /* OPLUS_FEATRUE_ESIM */
};

&pm8350_gpios {
	//#ifdef OPLUS_FEATRUE_DUAL_SIM_DETECT
	sim2_det_no_pull: sim2_det_no_pull {
			pins = "gpio8";
			function = "normal";
			input-enable;
			power-source = <1>;
			bias-disable;
	};

	sim2_det_pull_high: sim2_det_pull_high {
			pins = "gpio8";
			function = "normal";
			input-enable;
			power-source = <1>;
			bias-pull-up;
	};

	sim2_det_pull_low: sim2_det_pull_low {
			pins = "gpio8";
			function = "normal";
			input-enable;
			power-source = <1>;
			bias-pull-down;
	};
	//#endif OPLUS_FEATRUE_DUAL_SIM_DETECT
};

&soc {

    gpio_keys {
		compatible = "gpio-keys";
		label = "gpio-keys";

		pinctrl-names = "default";
		pinctrl-0 = <&key_vol_down_default>;
		// using volume down config update the default value
		vol_up {
			label = "volume_down";
			gpios = <&pm8350_gpios 6 GPIO_ACTIVE_LOW>;
			linux,input-type = <1>;
			linux,code = <KEY_VOLUMEDOWN>;
			gpio-key,wakeup;
			debounce-interval = <15>;
			linux,can-disable;
		};
	};

	qcom,qbt_handler {
		/delete-property/ qcom,ipc-gpio;
		//#ifdef OPLUS_FEATURE_FINGERPRINT
		status = "disabled";
		//#endif /*OPLUS_FEATURE_FINGERPRINT*/
	};

	extcon_usb1 {
		status = "disabled";
	};

	//#ifdef OPLUS_FEATRUE_ESIM
	oplus-gpio {
		compatible = "oplus,oplus-gpio";
		pinctrl-names = "default", "sim2_det_no_pull", "sim2_det_pull_high", "sim2_det_pull_low";
		pinctrl-0 = <&esim_gpio &esim_det_gpio &sim2_det_no_pull>;
		pinctrl-1 = <&sim2_det_no_pull>;
		pinctrl-2 = <&sim2_det_pull_high>;
		pinctrl-3 = <&sim2_det_pull_low>;
		oplus,oplus-gpio-esim = <&tlmm 6 0>;
		oplus,oplus-esim-det = <&tlmm 47 0>;
		oplus,oplus-sim2-det = <&pm8350_gpios 8 0>;
		oplus,uim-reset-pin = "modem_solution";
	};
	//#endif /* OPLUS_FEATRUE_ESIM */

	//#ifdef OPLUS_FEATRUE_SIM_HOLDER_DETECT
	oplus_sim_detect {
		compatible = "oplus, sim_detect";
		Hw,sim_det = "modem_det";
	};
	//#endif /* OPLUS_FEATRUE_SIM_HOLDER_DETECT */

	//#ifdef OPLUS_FEATURE_SENSOR_SMEM
	/*enum sensor_id { OPLUS_ACCEL,OPLUS_GYRO,OPLUS_MAG,OPLUS_LIGHT,OPLUS_PROXIMITY,OPLUS_SAR,OPLUS_CT,OPLUS_BAROMETER,SENSORS_NUM};*/
        sensor_fb: sensor_fb {
            compatible = "oplus,sensor-feedback";
            master-id  = <3>;
            smem-id    = <608>;
        };
	oplus_sensor {
		compatible = "oplus,sensor-devinfo";
		als-row-coe = <110>;
		/*enum {LSM6DSM = 0x01, BMI160 = 0x02, LSM6DS3 = 0x04, BMI260 = 0x08, LSM6DSO = 0x10};*/
		gsensor@0 {
			sensor-name = <0x10>;//LSM6DSO
			sensor-direction = <7>;
			sensor-index = <0>;//source num
			sensor-type = <0>;//OPLUS_ACCEL
			use-sois = <1>;
		};
		/* enum {AKM0991X = 0x01, MMC5x3x = 0x02};*/
		msensor@0 {
			sensor-name = <0x2>;//MMC5x3x
			sensor-direction = <1>;
			sensor-index = <0>;
			sensor-type = <2>;//OPLUS_MAG
			parameter-number= <18>;
			soft-mag-parameter = <9744 0 2232 0 189 0 939 0 9646 0 329 1 365 0 106 1 11525 0>;//e00 sign e01 sign...
		};
		/*enum {STK3A5X=0x01,TCS3701=0x02,TCS3408=0x04};*/
		lsensor@0 {
			sensor-name = <0x0>;//TCS3408 0-use other driver//compatible old
			sensor-index = <0>;
			sensor-type = <3>;//OPLUS_LIGHT
			als-type = <1>;
			is-unit-device = <0>;
			is-als-dri = <0>;
			als-factor = <110>;
			is_als_initialed = <0>;
			als_buffer_length = <10>;
		};
		psensor@0 {
			sensor-name = <0x1>;//STK33502
			sensor-index = <0>;
			sensor-type = <4>;//OPLUS_PROXIMITY
			bus-number = <1>;
			irq-number = <89>;
			ps-type = <1>;
			ps_saturation = <2600>;
			/*1-need close 2-close has contidition 0-not close*/
			is_need_close_pd = <0>;
			/*sensor-reg start*/
			parameter-number = <4>;
			sensor-reg = <0x01 0x31
						  0xDB 0x00>; //override special reg
			/*sensor-reg end*/
		};
		/* enum {SX9324 = 0x01} */
		ssensor@0 {
			sensor-name = <0x1>;//SX9324
			sensor-index = <0>;
			sensor-type = <5>;//OPLUS_SAR
		};
		/* enum {tcs3408 = 0x01  stk37600 = 0x02} */
		cctsensor@0 {
			sensor-name = <0x1>; //tcs3408
			sensor-index = <0>;
			sensor-type = <6>; //OPLUS_CCT
			bus-number = <1>;
			//feature
			para-matrix = <1>;
			publish-sensors = <0x7>; //bit[0] - als, bit[1] - rgb, bit[2] - flicker
			is-ch-dri = <0>;
			timer-size = <25>; //ms
			fac-cali-sensor = <0x2>; //0x1 - als, 0x2 - rgb, 0x4, flicker
		};
		cctrsensor@0 {
			sensor-name = <0x1>; //tcs3408
			sensor-index = <0>;
			sensor-type = <7>; //OPLUS_CCT_REAR
			bus-number = <5>;
			//feature
			publish-sensors = <0x7>; //bit[0] - als, bit[1] - rgb, bit[2] - flicker
			is-ch-dri = <0>;
			timer-size = <25>; //ms
			fac-cali-sensor = <0x2>; //0x1 - als, 0x2 - rgb, 0x4, flicker
		};
		/*virtual sensor
		enum sensor_algo_id {
			OPLUS_PICKUP_DETECT,
			OPLUS_LUX_AOD,
			OPLUS_TP_GESTURE,
			OPLUS_FP_DISPLAY,
			OPLUS_FREE_FALL,
			OPLUS_CAMERA_PROTECT,
			SENSOR_ALGO_NUM
		}*/
		pickup_detect {
			sensor-type = <0>;//OPLUS_PICKUP_DETECT
			is-virtual-sensor;
			is-need-prox = <1>;
			prox-type = <0>;
		};
		lux_aod {
			sensor-type = <1>; //OPLUS_LUX_AOD
			is-virtual-sensor;
			thrd-low = <12>;
			thrd-high = <50>;
			als-type = <0>;
		};
		fp_display {
			sensor-type = <3>;//OPLUS_FP_DISPLAY
			is-virtual-sensor;
			prox-type = <0>; // 0 - proximity; 1 - proximity_fake
		};
		free_fall {
			sensor-type = <4>;//OPLUS_FREE_FALL
			is-virtual-sensor;
		};
	};
	//#endif /*OPLUS_FEATURE_SENSOR_SMEM*/

	//#ifdef OPLUS_FEATURE_FINGERPRINT
	oplus_secure_common {
		compatible = "oplus,secure_common";
		oplus,sec_reg_num = <0x780668>;
		oplus,sec_en_anti_reg = <0x7801CC>;
		oplus,sec_override1_reg = <0x7860C0>;
		oplus,override1_en_value = <0x1>;
	};
	//#endif /*OPLUS_FEATURE_FINGERPRINT*/

	//#ifdef OPLUS_FEATURE_FINGERPRINT
	oplus_fp_common {
		compatible = "oplus,fp_common";
		oplus,fp_gpio_num = <1>;
		oplus,fp_gpio_0 = <&tlmm 119 0x0>;
		pinctrl-names = "default";
		pinctrl-0 = <&gpio_id2_default>;
		goodix_optical_G3S {
			oplus,fp-id = <1>; /* fp id mapping table */
			vendor-chip = <11>; /* please refer to the struct fp_vendor_t in oplus_fp_commmon.n */
			eng-menu = "-1,-1"; /* represents SNR, inclination test item in engineer menu, and 0/1 means off/on */
			chip-name = "G_OPTICAL_G3S";  /* /proc/fp_id, will be displayed in engineer menu  */
		};
	};
	goodix_fp {
		status = "ok";
		compatible = "goodix,goodix_fp";
		interrupt-parent = <&tlmm>;
		interrupts = <38 0>;
		ldo-supply = <&pm8350c_l11>;
		ldo-config = <3000000 3000000 150000>;
		goodix,gpio_irq = <&tlmm 38 0x1>;
		goodix,gpio_reset = <&tlmm 28 0x0>;
		pinctrl-names = "default";
		pinctrl-0 = <&gpio_goodix_irq_default>;
		notify_tpinfo_flag = <1>;
		power-num = <1>;
		power_source_1 {
			power-mode = <1>;
			power-name = "ldo";
			power-config = "ldo-config";
			delay-time = <0>;
		};
	};
	//#endif /*OPLUS_FEATURE_FINGERPRINT*/
};

&qupv3_se4_i2c {
	status = "okay";
	/delete-property/ qcom,i2c-touch-active;

	st_fts@49 {
		status = "disabled";
	};
	focaltech@38 {
		status = "disabled";
	};

	mtp_20031:synaptics20031@4B {
		compatible = "synaptics-s3908";
		reg = <0x4B>;
		chip-name = "S3908";

		/* Interrupt && Irq-gpio */
		interrupt-parent = <&tlmm>;
		interrupts = <23 0x2008>;

		/* Power Config */
		//enable2v8_gpio = <&tlmm 26 0x1>;
		//enable1v8_gpio = <&tlmm 6 0x1>;
		vdd_2v8-supply = <&L3C>;
		vcc_1v8-supply = <&L6C>;
		vdd_2v8_volt = <3008000>;

		/* Other HW Resource */
		irq-gpio = <&tlmm 23 0x2008>;
		reset-gpio = <&tlmm 22 0x1>;
		pinctrl-names = "default";
		pinctrl-0 = <&ts_int_active &ts_reset_active>;

		touchpanel,max-num-support = <10>;
		touchpanel,tx-rx-num = <17 38>;
		earsense,tx-rx-num = <17 18>;
		touchpanel,panel-coords = <5760 12864>;
		touchpanel,display-coords = <1440 3216>;
		touchpanel,touchmajor-limit = <256 256>;
		touchpanel,int-mode = <1>; /*0: interrupt and disable, 1:interrupt and not disable*/
		touchpanel,curved-size = <45>;

		touchpanel,smooth-level = <0 1 2 4 7 9>;
		touchpanel,smooth-level-charging = <0 2 4 7 8 9>;
		touchpanel,sensitive-level = <0 70 55 40 25 10>;
		touchpanel,single-optimized-time = <8>;

		end_stretch_value = <480 250 16 16>;

		touchpanel,tp_ic_type = <2>;
		panel_type = <8>;
		// type of tp_dev ,TP-SAMSUNG = 8;
		firmware_name = "SS";
		platform_support_project = <21051 0x2105A>;
		platform_support_project_dir = <21051 21051>;
		platform_support_project_commandline = "mdss_dsi_oplus20031_samsung_1440_3216_dsc_cmd";
		panel = <&dsi_oplus20031_samsung_1440_3216_dsc_cmd
		         &dsi_oplus20031_samsung_1440_3216_dsc_cmd_evt
		         &dsi_oplus20031_samsung_1440_3216_dsc_cmd_dvt
		         &dsi_oplus20031_samsung_1440_3216_dsc_cmd_dvt_id09
		         &dsi_oplus20031_samsung_1440_3216_dsc_cmd_dvt_id07>;

		prevention,curved_screen_V2;
		prevention,corner_eliminate_point_support;
		prevention,grip_disable_level = <6>;
		prevention,updelay_time_ms = <30>;
		prevention,makeup_cnt_weight = <4 1 2 2 2>;
		prevention,large_corner_range = <600 1400>;
		prevention,large_corner_judge_condition = <500 100 600 4 4>;
		prevention,trx_reject_condition = <8 7 7>;
		prevention,trx_strict_reject_condition = <8 5 5>;
		prevention,large_judge_time_ms = <500 50 40>;
		prevention,large_exit_condition = <8 8 2>;
		prevention,single_channel_width = <160 160>;
		prevention,normal_tap_condition = <10 300>;
		prevention,long_edge_condition = <230 90 180 80>;
		prevention,long_strict_edge_condition = <160 60>;
		prevention,long_fingerhold_condition = <50 6 4 4>;
		prevention,short_edge_condition = <200 90 180 80>;
		prevention,short_strict_edge_condition = <160 60>;
		prevention,large_strict_exit_condition = <2 2>;
		prevention,top_corner_config = <280 800 240>;
		prevention,edge_swipe_config = <150 400>;

		/* SW Support Feature Control */
		black_gesture_support;
		sportify_aod_gesture_support;
		//fw_edge_limit_support;
		pressure_report_support;
		charger_pump_support;
		game_switch_support;
		smart_gesture_support;
		fw_update_app_support;
		fingerprint_underscreen_support;
		freq_hop_simulate_support;
		report_flow_unlock_support;
		screenoff_fingerprint_info_support;
		irq_need_dev_resume_ok;
		//firmware_in_dts;
		enable_point_auto_change;
		report_rate_white_list_support;
		kernel_grip_support;
		//grip_no_driver_support;
		health_monitor_support;
		exception_upload_support;
		black_gesture_indep_support;
		//enable_touch_helper;

		/*
		 *Virtual Key Config:
		 *1:touchpanel,button-type: <virtualkey_type  supportted_button-map>
		 *virtualkey_type:
		 *Type 1: using board_properties
		 *Type 2: using same IC (button zone&& touch zone are seprate)
		 *Type 3: using diffrent IC (button zone&& touch zone are seprate)
		 *Type 4: No need of virtual key process
		 *supportted_button-map:select|menu|home|back
		 *
		 *2:touchpanel,button-map
		 *type (X1,Y1)(X2,Y2)(X3,Y3)(Width_X,Hight_Y)--Only when button-type is 0
		 */
		touchpanel,button-type = <4>;
		touchpanel.button-TRx = <0 0>;

		S3908 {
			report_rate_default = <60>;
			report_rate_game_value = <2>;
			default_gesture_mask = <8191>;
		};
	};

};

&sdhc_2 {
//	status = "ok";
	status = "disabled";
};


// #ifdef OPLUS_FEATURE_CHG_BASIC
&pm8350c_gpios {

	vbat_en_ctrl {
		vbat_en_active: vbat_en_active {
			pins = "gpio2";
			function = "normal";
			input-disable;
			output-enable;
			bias-disable;
			power-source = <1>;	/* 1.8V */
			qcom,drive-strength = <2>;
		};

		vbat_en_sleep: vbat_en_sleep {
			pins = "gpio2";
			function = "normal";
			input-disable;
			output-enable;
			bias-disable;
			power-source = <1>;	/* 1.8V */
			qcom,drive-strength = <2>;
		};

		vbat_en_default: vbat_en_default {
			pins = "gpio2";
			function = "normal";
			input-disable;
			output-enable;
			bias-disable;
			power-source = <1>;	/* 1.8V */
			qcom,drive-strength = <2>;
		};
	};

	booster_en_ctrl {
		booster_en_active: booster_en_active {
			pins = "gpio4";
			function = "normal";
			input-disable;
			output-enable;
			bias-disable;
			power-source = <1>;	/* 1.8V */
			qcom,drive-strength = <2>;
		};

		booster_en_sleep: booster_en_sleep {
			pins = "gpio4";
			function = "normal";
			input-disable;
			output-enable;
			bias-disable;
			power-source = <1>;	/* 1.8V */
			qcom,drive-strength = <2>;
		};

		booster_en_default: booster_en_default {
			pins = "gpio4";
			function = "normal";
			input-disable;
			output-enable;
			bias-disable;
			power-source = <1>;	/* 1.8V */
			qcom,drive-strength = <2>;
		};
	};

	wrx_en_ctrl {
		wrx_en_active: wrx_en_active {
			pins = "gpio6";
			function = "normal";
			input-disable;
			output-enable;
			bias-disable;
			power-source = <1>;	/* 1.8V */
			qcom,drive-strength = <2>;
		};

		wrx_en_sleep: wrx_en_sleep {
			pins = "gpio6";
			function = "normal";
			input-disable;
			output-enable;
			bias-disable;
			power-source = <1>;	/* 1.8V */
			qcom,drive-strength = <2>;
		};

		wrx_en_default: wrx_en_default {
			pins = "gpio6";
			function = "normal";
			input-disable;
			output-enable;
			bias-disable;
			power-source = <1>;	/* 1.8V */
			qcom,drive-strength = <2>;
		};
	};

	wrx_otg_en_ctrl {
		wrx_otg_en_active: wrx_otg_en_active {
			pins = "gpio7";
			function = "normal";
			input-disable;
			output-enable;
			bias-disable;
			power-source = <1>;	/* 1.8V */
			qcom,drive-strength = <2>;
		};

		wrx_otg_en_sleep: wrx_otg_en_sleep {
			pins = "gpio7";
			function = "normal";
			input-disable;
			output-enable;
			bias-disable;
			power-source = <1>;	/* 1.8V */
			qcom,drive-strength = <2>;
		};
		wrx_otg_en_default: wrx_otg_en_default {
			pins = "gpio7";
			function = "normal";
			input-disable;
			output-enable;
			bias-disable;
			power-source = <1>;	/* 1.8V */
			qcom,drive-strength = <2>;
		};
	};

	mps_otg_en_ctrl {
		mps_otg_en_active: mps_otg_en_active {
			pins = "gpio1";
			function = "normal";
			input-disable;
			//output-enable;
			output-high;
			bias-disable;
			power-source = <1>;	/* 1.8V */
			qcom,drive-strength = <2>;
		};

		mps_otg_en_sleep: mps_otg_en_sleep {
			pins = "gpio1";
			function = "normal";
			input-disable;
			//output-enable;
			output-low;
			bias-disable;
			power-source = <1>;	/* 1.8V */
			qcom,drive-strength = <2>;
		};
		mps_otg_en_default: mps_otg_en_default {
			pins = "gpio1";
			function = "normal";
			input-disable;
			//output-enable;
			output-low;
			bias-disable;
			power-source = <1>;	/* 1.8V */
			qcom,drive-strength = <2>;
		};
	};
};

&qupv3_se0_i2c {

	status = "ok";

	mp2650-charger@5c {
		status = "okay";
		compatible = "oplus,mp2650-charger";
		reg = <0x5c 0>;

		qcom,mps_otg_en-gpio = <&pm8350c_gpios 1 0x00>;
		pinctrl-names = "mps_otg_en_active", "mps_otg_en_sleep", "mps_otg_en_default";
		pinctrl-0 = <&mps_otg_en_active>;
		pinctrl-1 = <&mps_otg_en_sleep>;
		pinctrl-2 = <&mps_otg_en_default>;
	};

	nu1619-charger@61 {    //sp6001
		status = "ok";
		compatible = "oplus,nu1619-charger";
		reg = <0x61 0>;	   //sp6001

		qcom,bpp_input_ma = <750>;
		qcom,epp_input_ma = <800>;
		qcom,epp_input_step_ma = <100>;
		qcom,vooc_input_ma = <1000>;
		qcom,vooc_iout_ma = <1000>;
		qcom,svooc_input_ma = <1000>;
		qcom,svooc_65w_iout_ma = <2300>;
		qcom,svooc_50w_iout_ma = <1750>;

		qcom,bpp_temp_cold_fastchg_ma = <300>;						// -2

		qcom,vooc_temp_little_cold_fastchg_ma = <1200>;		// 0
		qcom,svooc_temp_little_cold_iout_ma = <650>;
		qcom,svooc_temp_little_cold_fastchg_ma = <1200>;
		qcom,bpp_temp_little_cold_fastchg_ma = <600>;
		qcom,epp_temp_little_cold_fastchg_ma = <1400>;

		qcom,vooc_temp_cool_fastchg_ma = <1200>;				// 5
		qcom,svooc_temp_cool_iout_ma = <650>;
		qcom,svooc_temp_cool_fastchg_ma = <1200>;
		qcom,bpp_temp_cool_fastchg_ma = <600>;
		qcom,epp_temp_cool_fastchg_ma = <1400>;

		qcom,vooc_temp_little_cool_fastchg_ma = <1200>;		// 12
		qcom,svooc_temp_little_cool_fastchg_ma = <1200>;
		qcom,bpp_temp_little_cool_fastchg_ma = <600>;
		qcom,epp_temp_little_cool_fastchg_ma = <1400>;

		qcom,vooc_temp_normal_fastchg_ma = <1200>;		// 16
		qcom,svooc_temp_normal_fastchg_ma = <1200>;
		qcom,bpp_temp_normal_fastchg_ma = <600>;
		qcom,epp_temp_normal_fastchg_ma = <1400>;

		qcom,vooc_temp_warm_fastchg_ma = <1200>;		// 45
		qcom,svooc_temp_warm_fastchg_ma = <1200>;
		qcom,bpp_temp_warm_fastchg_ma = <600>;
		qcom,epp_temp_warm_fastchg_ma = <1400>;

		qcom,curr_cp_to_charger = <400>;
		qcom,support_airsvooc = <1>;
		qcom,phone_id = <0x07>;
		qcom,svooc_target_ichg_cold_fastchg_ma = <500>;              // -2

		qcom,svooc_target_ichg_little_cold_fastchg_ma = <1500>;      // 0
		qcom,vooc_target_ichg_little_cold_fastchg_ma = <1200>;
		qcom,bpp_target_ichg_little_cold_fastchg_ma = <500>;
		qcom,epp1_target_ichg_little_cold_fastchg_ma = <500>;      //EPP8W
		qcom,epp2_target_ichg_little_cold_fastchg_ma = <1000>;      //EPP10W
		qcom,epp3_target_ichg_little_cold_fastchg_ma = <1500>;      //EPP15W

		qcom,svooc_target_ichg_cool_fastchg_ma = <2000>;      //5
		qcom,vooc_target_ichg_cool_fastchg_ma = <1200>;
		qcom,bpp_target_ichg_cool_fastchg_ma = <500>;
		qcom,epp1_target_ichg_cool_fastchg_ma = <500>;      //EPP8W
		qcom,epp2_target_ichg_cool_fastchg_ma = <1000>;      //EPP10W
		qcom,epp3_target_ichg_cool_fastchg_ma = <1500>;      //EPP15W

		qcom,svooc_target_ichg_normal_region1_fastchg_ma = <3000>;      //12
		qcom,vooc_target_ichg_normal_region1_fastchg_ma = <1200>;
		qcom,bpp_target_ichg_normal_region1_fastchg_ma = <500>;
		qcom,epp1_target_ichg_normal_region1_fastchg_ma = <500>;      //EPP8W
		qcom,epp2_target_ichg_normal_region1_fastchg_ma = <1000>;      //EPP10W
		qcom,epp3_target_ichg_normal_region1_fastchg_ma = <1500>;      //EPP15W

		qcom,svooc_target_ichg_normal_region2_fastchg_ma = <1500>;      //37.5
		qcom,vooc_target_ichg_normal_region2_fastchg_ma = <1200>;
		qcom,bpp_target_ichg_normal_region2_fastchg_ma = <500>;
		qcom,epp1_target_ichg_normal_region2_fastchg_ma = <500>;      //EPP8W
		qcom,epp2_target_ichg_normal_region2_fastchg_ma = <1000>;      //EPP10W
		qcom,epp3_target_ichg_normal_region2_fastchg_ma = <1000>;      //EPP15W

		qcom,svooc_target_ichg_normal_region3_fastchg_ma = <1200>;      //40
		qcom,vooc_target_ichg_normal_region3_fastchg_ma = <500>;
		qcom,bpp_target_ichg_normal_region3_fastchg_ma = <500>;
		qcom,epp_target_ichg_normal_region3_fastchg_ma = <500>;

		qcom,svooc_target_ichg_warm_fastchg_ma = <500>;      //45
		qcom,wireless_power = <30>;

		ffc_target_ichg_table = <5000 3000 1850     //vbatt,target_ichg,input_current
								 5000 2500 1550
								 5000 2000 1250
								 5000 1500 950
								 5000 1200 950
								 5000 1000 800
								 5000 700 700
								 5000 550 500
								 5000 500 400
								 5000 350 400
								 0 0 0>;

		svooc_target_ichg_table = <3700 3000 1600     //vbatt,target_ichg,input_current
								   3700 2500 1350
								   3700 2000 1100
								   3700 1500 850
								   3900 3000 1700
								   3900 2500 1450
								   3900 2000 1200
								   3900 1500 900
								   4100 3000 1800
								   4100 2500 1500
								   4100 2000 1200
								   4100 1500 900
								   5000 3000 1850
								   5000 2500 1550
								   5000 2000 1250
								   5000 1500 950
								   5000 1200 950
								   5000 500 400
								   5000 400 300
								   0 0 0>;

		vooc_target_ichg_table = <5000 1200 950     //vbatt,target_ichg,input_current
								  5000 500 400
								  5000 400 300
								  5000 200 400
								  0 0 0>;

		epp_target_ichg_table = <5000 1500 1200     //vbatt,target_ichg,input_current
								 5000 1000 800
								 5000 500 400
								 5000 400 300
								 0 0 0>;

		bpp_target_ichg_table = <5000 500 750     //vbatt,target_ichg,input_current
								 5000 200 400
								 0 0 0>;

		fasctchg_current_level = <0			/*FASTCHARGE_LEVEL_UNKNOW*/
							3000		/*FASTCHARGE_LEVEL_1*/
							2500		/*FASTCHARGE_LEVEL_2*/
							2000		/*FASTCHARGE_LEVEL_3*/
							1500		/*FASTCHARGE_LEVEL_4*/
							1200		/*FASTCHARGE_LEVEL_5*/
							1000		/*FASTCHARGE_LEVEL_6*/
							700		    /*FASTCHARGE_LEVEL_7*/
							550		    /*FASTCHARGE_LEVEL_8*/
							500		    /*FASTCHARGE_LEVEL_9*/
							350>;	    /*FASTCHARGE_LEVEL_10*/
		ffc_max_vol_level = <0 4300 4330 4360 4390 4400 0 4460 4445 0 4440>;  /*LEVEL1~10*/
		non_ffc_max_vol_level = <0 4230 4260 4290 4320 4340 4350 0 0 4400>;   /*LEVEL1~9*/

		pinctrl-names = "idt_int_active", "idt_int_sleep", "idt_int_default",
						"idt_connect_active", "idt_connect_sleep", "idt_connect_default",
						"vt_sleep_active", "vt_sleep_sleep", "vt_sleep_default",
						"booster_en_active", "booster_en_sleep", "booster_en_default",
						"ext2_wireless_otg_en_active", "ext2_wireless_otg_en_sleep", "ext2_wireless_otg_en_default",
						"ext1_wired_otg_en_active","ext1_wired_otg_en_sleep","ext1_wired_otg_en_default",
						"vbat_en_active","vbat_en_sleep","vbat_en_default",
						"wrx_en_active", "wrx_en_sleep", "wrx_en_default",
						"wrx_otg_en_active", "wrx_otg_en_sleep", "wrx_otg_en_default",
						"wls_pg_default", "wls_pg_active";

		pinctrl-0 = <&idt_int_active>;
		pinctrl-1 = <&idt_int_sleep>;
		pinctrl-2 = <&idt_int_default>;
		pinctrl-3 = <&idt_connect_active>;
		pinctrl-4 = <&idt_connect_sleep>;
		pinctrl-5 = <&idt_connect_default>;
		pinctrl-6 = <&vt_sleep_active>;
		pinctrl-7 = <&vt_sleep_sleep>;
		pinctrl-8 = <&vt_sleep_default>;
		pinctrl-9 = <&booster_en_active>;
		pinctrl-10 = <&booster_en_sleep>;
		pinctrl-11 = <&booster_en_default>;
		pinctrl-12 = <&ext2_wireless_otg_en_active>;
		pinctrl-13 = <&ext2_wireless_otg_en_sleep>;
		pinctrl-14 = <&ext2_wireless_otg_en_default>;
		pinctrl-15 = <&ext1_wired_otg_en_active>;
		pinctrl-16 = <&ext1_wired_otg_en_sleep>;
		pinctrl-17 = <&ext1_wired_otg_en_default>;
		pinctrl-18 = <&vbat_en_active>;
		pinctrl-19 = <&vbat_en_sleep>;
		pinctrl-20 = <&vbat_en_default>;
		pinctrl-21 = <&wrx_en_active>;
		pinctrl-22 = <&wrx_en_sleep>;
		pinctrl-23 = <&wrx_en_default>;
		pinctrl-24 = <&wrx_otg_en_active>;
		pinctrl-25 = <&wrx_otg_en_sleep>;
		pinctrl-26 = <&wrx_otg_en_default>;
		pinctrl-27 = <&wls_pg_default>;
		pinctrl-28 = <&wls_pg_active>;

		qcom,idt_int-gpio = <&tlmm 7 0x00>;   		//check
		qcom,idt_connect-gpio = <&tlmm 116 0x00>;	//check
		qcom,vt_sleep-gpio = <&tlmm 46 0x00>;			//pm8350c
		qcom,booster_en-gpio = <&pm8350c_gpios 4 0x00>;		//check
		qcom,ext1_wired_otg_en-gpio = <&tlmm 26 0x00>;	//check
		qcom,ext2_wireless_otg_en-gpio = <&tlmm 85 0x00>;		//check
		qcom,vbat_en-gpio = <&pm8350c_gpios 2 0x00>;		//pm8350c
		qcom,wrx_en-gpio = <&pm8350c_gpios 6 0x00>;
		qcom,wrx_otg_en-gpio = <&pm8350c_gpios 7 0x00>;
		qcom,wls_pg-gpio = <&tlmm 164 0x00>;
	};
};
#include "opluschg_wireless_fw.dtsi"

//#ifdef OPLUS_FEATURE_CHG_BASIC
&qupv3_se1_i2c {
	status = "ok";
	qcom,clk-freq-out = <100000>;

	da9313-divider@68 {
		status = "okay";
		compatible = "oplus,da9313-divider";
		reg = <0x68 0>;
	};
};

&thermal_zones {
	tof-therm-usr {
		status = "disabled";
	};
};
//#endif

&pm8350b_haptics {
	status = "ok";
//#ifdef OPLUS_FEATURE_CHG_BASIC
	qcom,vmax-mv = <1900>;
	qcom,cl-vmax-mv = <2550>;
	qcom,lra-period-us = <4255>;
	qcom,fifo-vmax-mv = <8900>;
	qcom,old-steady-vmax-mv = <9700>;
	qcom,cal-data-restore;
//#endif
};

&usb1 {
	/delete-property/ extcon;
	status = "disabled";
	dwc3@a800000 {
		status = "disabled";
	};

//#endif
};

//#ifdef OPLUS_FEATURE_FINGERPRINT
&removed_mem {
	no-map;
	//reg = <0x0 0xd8800000 0x0 0x9800000>;
	reg = <0x0 0xd8800000 0x0 0x8e00000>;
};
&splash_memory {
	//reg = <0x0 0xe5700000 0x0 0x02300000>;
	reg = <0x0 0xe4d00000 0x0 0x02300000>;
	label = "cont_splash_region";
};

&disp_rdump_memory {
	//reg = <0xe5700000 0x00800000>;
	reg = <0xe4d00000 0x00800000>;
	label = "disp_rdump_region";
};

&dfps_data_memory {
	//reg = <0x0 0xe7a00000 0x0 0x0100000>;
	reg = <0x0 0xe7000000 0x0 0x0100000>;
	label = "dfps_data_region";
};
//#endif /*OPLUS_FEATURE_FINGERPRINT*/

// #ifdef OPLUS_SYSTEM_UBOOT_LOG
// xbl_uefi_mem address get from boot_images Core.dsc.inc file: PcdEmbeddedFdBaseAddress + SERIAL_BUFFER_OFFSET,0x9FE00000+0x1F7000=0x9FFF7000
// kernel boot log: 0x9FE00000~ 0x9FFF7000
&reserved_memory {
		kboot_uboot_logmem: kboot_uboot_logmem@0x9FE00000 {
			reg = <0x0 0x9FE00000 0x0 0x200000>;
			compatible = "oplus,xbl_uefi_kbootlog";
			xbluefi-offset = <0x1F7000>;
			no-map;
		};
//#if IS_ENABLED(CONFIG_OPLUS_FEATURE_DUMP_DEVICE_INFO)
    ramoops: ramoops@0xE9700000 {
        compatible = "ramoops";
        reg = <0 0xE9700000 0 0x05B8000>; //5M + 736k
        record-size =  <0x40000>; //256k
        console-size = <0x40000>; //256k
        ftrace-size =  <0x200000>; //2M
        pmsg-size=     <0x200000>; //2M
        devinfo-size=  <0x08000>;  //32k
        dumpinfo-size=  <0x08000>; //32k
        rsv01info-size=  <0x08000>; //32k
        rsv02info-size=  <0x08000>; //32k
        rsv03info-size=  <0x08000>; //32k
        rsv04info-size=  <0x08000>; //32k
        rsv05info-size=  <0x08000>; //32k
        ecc-size=      <0x0>;
    };
//#endif
};
// #endif

//#ifndef OPLUS_FEATURE_DEVICE_LOG
&memshare_mem {
	compatible = "shared-dma-pool";
	size = <0x0 0x1200000>;
};
//#endif

//#ifdef OPLUS_BUG_STABILITY
&wlan {
	use-nv-mac;
};
//#endif /* OPLUS_BUG_STABILITY */

&soc {
	oplus_rf_cable {
		compatible = "oplus,rf_cable";
		interrupt-parent = <&tlmm>;
		rf_cable_support_num = <1>;
		rf,cable0-gpio = <&tlmm 91 0>;
		rf,cable-support-timer = <0>;
		pinctrl-names = "rf_cable_active";
		pinctrl-0 = <&rf_cable0_active>;
	};
	//#ifndef OPLUS_FEATURE_DEVICE_LOG
	qcom,memshare {
		qcom,client_3 {
			compatible = "qcom,memshare-peripheral";
			qcom,peripheral-size = <0xF00000>;
		};
	};
	//#endif
};

//#ifdef OPLUS_FEATURE_CHG_BASIC
&usb0 {
	dwc3@a600000 {
		snps,usb2-lpm-disable;
	};
};
//#endif /* OPLUS_FEATURE_CHG_BASIC */

//#ifdef OPLUS_FEATURE_THERMAL
&thermal_zones {
	cpu-gold-0-0-step {
		polling-delay-passive = <10>;
		polling-delay = <0>;
		thermal-sensors = <&tsens0 7>;
		thermal-governor = "step_wise";
		trips {
			cg00_config: cg00-config {
				temperature = <80000>;
				hysteresis = <3000>;
				type = "passive";
			};
		};

		cooling-maps {
			cg00_cdev {
				trip = <&cg00_config>;
				cooling-device = <&CPU4 THERMAL_NO_LIMIT
							(THERMAL_MAX_LIMIT - 8)>;
			};
		};
	};

	cpu-gold-0-1-step {
		polling-delay-passive = <10>;
		polling-delay = <0>;
		thermal-sensors = <&tsens0 8>;
		thermal-governor = "step_wise";
		trips {
			cg01_config: cg01-config {
				temperature = <80000>;
				hysteresis = <3000>;
				type = "passive";
			};
		};

		cooling-maps {
			cg01_cdev {
				trip = <&cg01_config>;
				cooling-device = <&CPU4 THERMAL_NO_LIMIT
							(THERMAL_MAX_LIMIT - 8)>;
			};
		};
	};

	cpu-gold-1-0-step {
		polling-delay-passive = <10>;
		polling-delay = <0>;
		thermal-sensors = <&tsens0 9>;
		thermal-governor = "step_wise";
		trips {
			cg10_config: cg10-config {
				temperature = <80000>;
				hysteresis = <3000>;
				type = "passive";
			};
		};

		cooling-maps {
			cg10_cdev {
				trip = <&cg10_config>;
				cooling-device = <&CPU5 THERMAL_NO_LIMIT
							(THERMAL_MAX_LIMIT - 8)>;
			};
		};
	};

	cpu-gold-1-1-step {
		polling-delay-passive = <10>;
		polling-delay = <0>;
		thermal-sensors = <&tsens0 10>;
		thermal-governor = "step_wise";
		trips {
			cg11_config: cg11-config {
				temperature = <80000>;
				hysteresis = <3000>;
				type = "passive";
			};
		};

		cooling-maps {
			cg11_cdev {
				trip = <&cg11_config>;
				cooling-device = <&CPU4 THERMAL_NO_LIMIT
							(THERMAL_MAX_LIMIT - 8)>;
			};
		};
	};

	cpu-gold-2-0-step {
		polling-delay-passive = <10>;
		polling-delay = <0>;
		thermal-sensors = <&tsens0 11>;
		thermal-governor = "step_wise";
		trips {
			cg20_config: cg20-config {
				temperature = <80000>;
				hysteresis = <3000>;
				type = "passive";
			};
		};

		cooling-maps {
			cg20_cdev {
				trip = <&cg20_config>;
				cooling-device = <&CPU4 THERMAL_NO_LIMIT
							(THERMAL_MAX_LIMIT - 8)>;
			};
		};
	};

	cpu-gold-2-1-step {
		polling-delay-passive = <10>;
		polling-delay = <0>;
		thermal-sensors = <&tsens0 12>;
		thermal-governor = "step_wise";
		trips {
			cg21_config: cg21-config {
				temperature = <80000>;
				hysteresis = <3000>;
				type = "passive";
			};
		};

		cooling-maps {
			cg21_cdev {
				trip = <&cg21_config>;
				cooling-device = <&CPU4 THERMAL_NO_LIMIT
							(THERMAL_MAX_LIMIT - 8)>;
			};
		};
	};

	cpu-gold-3-0-step {
		polling-delay-passive = <10>;
		polling-delay = <0>;
		thermal-sensors = <&tsens0 13>;
		thermal-governor = "step_wise";
		trips {
			cg30_config: cg30-config {
				temperature = <80000>;
				hysteresis = <3000>;
				type = "passive";
			};
		};

		cooling-maps {
			cg30_cdev {
				trip = <&cg30_config>;
				cooling-device = <&CPU7 THERMAL_NO_LIMIT
							(THERMAL_MAX_LIMIT - 8)>;
			};
		};
	};

	cpu-gold-3-1-step {
		polling-delay-passive = <10>;
		polling-delay = <0>;
		thermal-sensors = <&tsens0 14>;
		thermal-governor = "step_wise";
		trips {
			cg31_config: cg31-config {
				temperature = <80000>;
				hysteresis = <3000>;
				type = "passive";
			};
		};

		cooling-maps {
			cg31_cdev {
				trip = <&cg31_config>;
				cooling-device = <&CPU7 THERMAL_NO_LIMIT
							(THERMAL_MAX_LIMIT - 8)>;
			};
		};
	};
};
//#endif OPLUS_FEATURE_THERMAL
